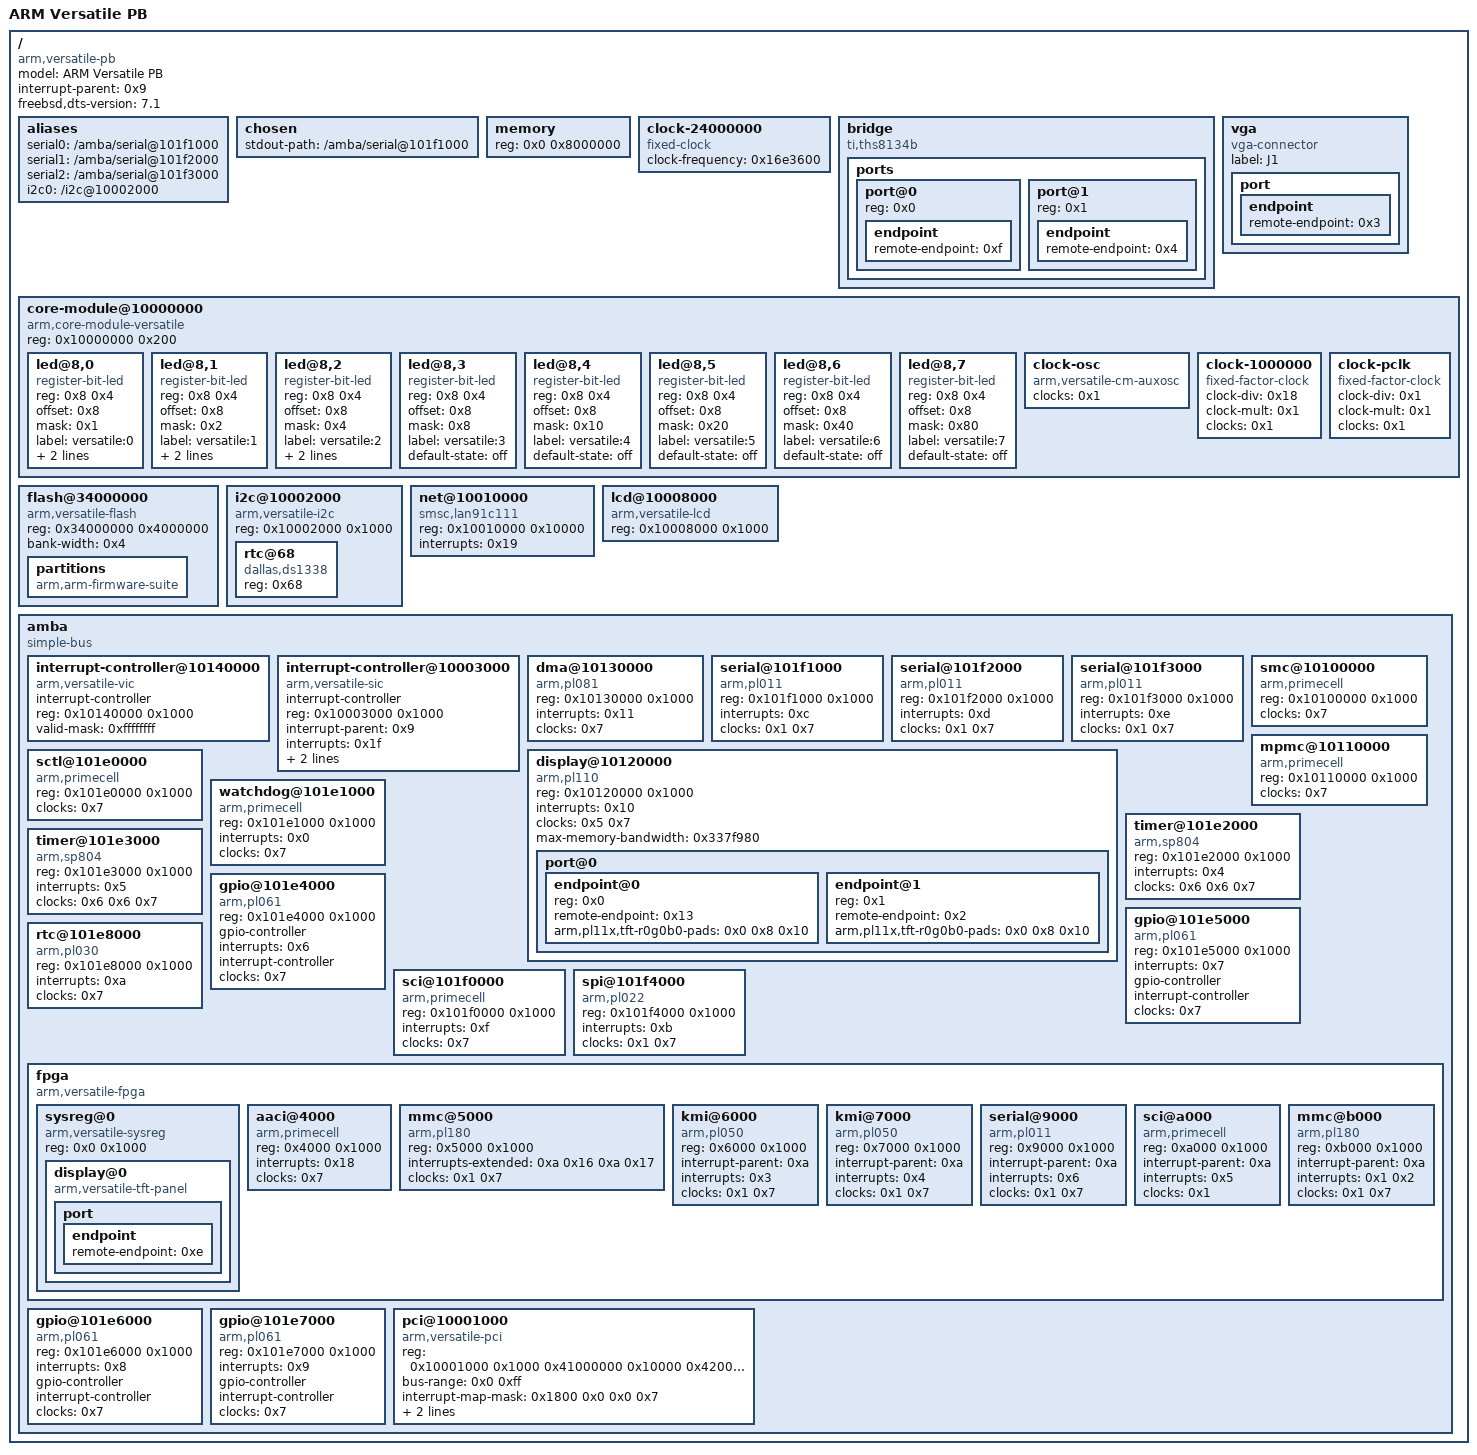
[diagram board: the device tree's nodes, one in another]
/dts-v1/;

/  {

	model = "ARM Versatile PB";
	compatible = "arm,versatile-pb";
	#address-cells = <0x1>;
	#size-cells = <0x1>;
	interrupt-parent = <0x9>;
	freebsd,dts-version = "7.1";
	aliases {

		serial0 = "/amba/serial@101f1000";
		serial1 = "/amba/serial@101f2000";
		serial2 = "/amba/serial@101f3000";
		i2c0 = "/i2c@10002000";
	};
	chosen {

		stdout-path = "/amba/serial@101f1000";
	};
	memory {

		device_type = "memory";
		reg = <0x0 0x8000000>;
	};
	clock-24000000 {

		#clock-cells = <0x0>;
		compatible = "fixed-clock";
		clock-frequency = <0x16e3600>;
		phandle = <0x1>;
	};
	bridge {

		compatible = "ti,ths8134b", "ti,ths8134";
		ports {

			#address-cells = <0x1>;
			#size-cells = <0x0>;
			port@0 {

				reg = <0x0>;
				endpoint {

					remote-endpoint = <0xf>;
					phandle = <0x2>;
				};
			};
			port@1 {

				reg = <0x1>;
				endpoint {

					remote-endpoint = <0x4>;
					phandle = <0x3>;
				};
			};
		};
	};
	vga {

		compatible = "vga-connector";
		label = "J1";
		port {

			endpoint {

				remote-endpoint = <0x3>;
				phandle = <0x4>;
			};
		};
	};
	core-module@10000000 {

		compatible = "arm,core-module-versatile", "syscon", "simple-mfd";
		reg = <0x10000000 0x200>;
		ranges = <0x0 0x10000000 0x200>;
		#address-cells = <0x1>;
		#size-cells = <0x1>;
		led@8,0 {

			compatible = "register-bit-led";
			reg = <0x8 0x4>;
			offset = <0x8>;
			mask = <0x1>;
			label = "versatile:0";
			linux,default-trigger = "heartbeat";
			default-state = "on";
		};
		led@8,1 {

			compatible = "register-bit-led";
			reg = <0x8 0x4>;
			offset = <0x8>;
			mask = <0x2>;
			label = "versatile:1";
			linux,default-trigger = "mmc0";
			default-state = "off";
		};
		led@8,2 {

			compatible = "register-bit-led";
			reg = <0x8 0x4>;
			offset = <0x8>;
			mask = <0x4>;
			label = "versatile:2";
			linux,default-trigger = "cpu0";
			default-state = "off";
		};
		led@8,3 {

			compatible = "register-bit-led";
			reg = <0x8 0x4>;
			offset = <0x8>;
			mask = <0x8>;
			label = "versatile:3";
			default-state = "off";
		};
		led@8,4 {

			compatible = "register-bit-led";
			reg = <0x8 0x4>;
			offset = <0x8>;
			mask = <0x10>;
			label = "versatile:4";
			default-state = "off";
		};
		led@8,5 {

			compatible = "register-bit-led";
			reg = <0x8 0x4>;
			offset = <0x8>;
			mask = <0x20>;
			label = "versatile:5";
			default-state = "off";
		};
		led@8,6 {

			compatible = "register-bit-led";
			reg = <0x8 0x4>;
			offset = <0x8>;
			mask = <0x40>;
			label = "versatile:6";
			default-state = "off";
		};
		led@8,7 {

			compatible = "register-bit-led";
			reg = <0x8 0x4>;
			offset = <0x8>;
			mask = <0x80>;
			label = "versatile:7";
			default-state = "off";
		};
		clock-osc {

			#clock-cells = <0x0>;
			compatible = "arm,versatile-cm-auxosc";
			clocks = <0x1>;
			phandle = <0x5>;
		};
		clock-1000000 {

			#clock-cells = <0x0>;
			compatible = "fixed-factor-clock";
			clock-div = <0x18>;
			clock-mult = <0x1>;
			clocks = <0x1>;
			phandle = <0x6>;
		};
		clock-pclk {

			#clock-cells = <0x0>;
			compatible = "fixed-factor-clock";
			clock-div = <0x1>;
			clock-mult = <0x1>;
			clocks = <0x1>;
			phandle = <0x7>;
		};
	};
	flash@34000000 {

		compatible = "arm,versatile-flash", "cfi-flash";
		reg = <0x34000000 0x4000000>;
		bank-width = <0x4>;
		partitions {

			compatible = "arm,arm-firmware-suite";
		};
	};
	i2c@10002000 {

		#address-cells = <0x1>;
		#size-cells = <0x0>;
		compatible = "arm,versatile-i2c";
		reg = <0x10002000 0x1000>;
		phandle = <0x8>;
		rtc@68 {

			compatible = "dallas,ds1338";
			reg = <0x68>;
		};
	};
	net@10010000 {

		compatible = "smsc,lan91c111";
		reg = <0x10010000 0x10000>;
		interrupts = <0x19>;
	};
	lcd@10008000 {

		compatible = "arm,versatile-lcd";
		reg = <0x10008000 0x1000>;
	};
	amba {

		compatible = "simple-bus";
		#address-cells = <0x1>;
		#size-cells = <0x1>;
		ranges;
		interrupt-controller@10140000 {

			compatible = "arm,versatile-vic";
			interrupt-controller;
			#interrupt-cells = <0x1>;
			reg = <0x10140000 0x1000>;
			valid-mask = <0xffffffff>;
			phandle = <0x9>;
		};
		interrupt-controller@10003000 {

			compatible = "arm,versatile-sic";
			interrupt-controller;
			#interrupt-cells = <0x1>;
			reg = <0x10003000 0x1000>;
			interrupt-parent = <0x9>;
			interrupts = <0x1f>;
			clear-mask = <0xffffffff>;
			valid-mask = <0x7fe003ff>;
			phandle = <0xa>;
		};
		dma@10130000 {

			compatible = "arm,pl081", "arm,primecell";
			reg = <0x10130000 0x1000>;
			interrupts = <0x11>;
			clocks = <0x7>;
			clock-names = "apb_pclk";
		};
		serial@101f1000 {

			compatible = "arm,pl011", "arm,primecell";
			reg = <0x101f1000 0x1000>;
			interrupts = <0xc>;
			clocks = <0x1 0x7>;
			clock-names = "uartclk", "apb_pclk";
			phandle = <0xb>;
		};
		serial@101f2000 {

			compatible = "arm,pl011", "arm,primecell";
			reg = <0x101f2000 0x1000>;
			interrupts = <0xd>;
			clocks = <0x1 0x7>;
			clock-names = "uartclk", "apb_pclk";
			phandle = <0xc>;
		};
		serial@101f3000 {

			compatible = "arm,pl011", "arm,primecell";
			reg = <0x101f3000 0x1000>;
			interrupts = <0xe>;
			clocks = <0x1 0x7>;
			clock-names = "uartclk", "apb_pclk";
			phandle = <0xd>;
		};
		smc@10100000 {

			compatible = "arm,primecell";
			reg = <0x10100000 0x1000>;
			clocks = <0x7>;
			clock-names = "apb_pclk";
		};
		mpmc@10110000 {

			compatible = "arm,primecell";
			reg = <0x10110000 0x1000>;
			clocks = <0x7>;
			clock-names = "apb_pclk";
		};
		display@10120000 {

			compatible = "arm,pl110", "arm,primecell";
			reg = <0x10120000 0x1000>;
			interrupts = <0x10>;
			clocks = <0x5 0x7>;
			clock-names = "clcdclk", "apb_pclk";
			max-memory-bandwidth = <0x337f980>;
			port@0 {

				#address-cells = <0x1>;
				#size-cells = <0x0>;
				endpoint@0 {

					reg = <0x0>;
					remote-endpoint = <0x13>;
					arm,pl11x,tft-r0g0b0-pads = <0x0 0x8 0x10>;
					phandle = <0xe>;
				};
				endpoint@1 {

					reg = <0x1>;
					remote-endpoint = <0x2>;
					arm,pl11x,tft-r0g0b0-pads = <0x0 0x8 0x10>;
					phandle = <0xf>;
				};
			};
		};
		sctl@101e0000 {

			compatible = "arm,primecell";
			reg = <0x101e0000 0x1000>;
			clocks = <0x7>;
			clock-names = "apb_pclk";
		};
		watchdog@101e1000 {

			compatible = "arm,primecell";
			reg = <0x101e1000 0x1000>;
			interrupts = <0x0>;
			clocks = <0x7>;
			clock-names = "apb_pclk";
		};
		timer@101e2000 {

			compatible = "arm,sp804", "arm,primecell";
			reg = <0x101e2000 0x1000>;
			interrupts = <0x4>;
			clocks = <0x6 0x6 0x7>;
			clock-names = "timer0", "timer1", "apb_pclk";
		};
		timer@101e3000 {

			compatible = "arm,sp804", "arm,primecell";
			reg = <0x101e3000 0x1000>;
			interrupts = <0x5>;
			clocks = <0x6 0x6 0x7>;
			clock-names = "timer0", "timer1", "apb_pclk";
		};
		gpio@101e4000 {

			compatible = "arm,pl061", "arm,primecell";
			reg = <0x101e4000 0x1000>;
			gpio-controller;
			interrupts = <0x6>;
			#gpio-cells = <0x2>;
			interrupt-controller;
			#interrupt-cells = <0x2>;
			clocks = <0x7>;
			clock-names = "apb_pclk";
			phandle = <0x10>;
		};
		gpio@101e5000 {

			compatible = "arm,pl061", "arm,primecell";
			reg = <0x101e5000 0x1000>;
			interrupts = <0x7>;
			gpio-controller;
			#gpio-cells = <0x2>;
			interrupt-controller;
			#interrupt-cells = <0x2>;
			clocks = <0x7>;
			clock-names = "apb_pclk";
			phandle = <0x11>;
		};
		rtc@101e8000 {

			compatible = "arm,pl030", "arm,primecell";
			reg = <0x101e8000 0x1000>;
			interrupts = <0xa>;
			clocks = <0x7>;
			clock-names = "apb_pclk";
		};
		sci@101f0000 {

			compatible = "arm,primecell";
			reg = <0x101f0000 0x1000>;
			interrupts = <0xf>;
			clocks = <0x7>;
			clock-names = "apb_pclk";
		};
		spi@101f4000 {

			compatible = "arm,pl022", "arm,primecell";
			reg = <0x101f4000 0x1000>;
			interrupts = <0xb>;
			clocks = <0x1 0x7>;
			clock-names = "sspclk", "apb_pclk";
		};
		fpga {

			compatible = "arm,versatile-fpga", "simple-bus";
			#address-cells = <0x1>;
			#size-cells = <0x1>;
			ranges = <0x0 0x10000000 0x10000>;
			sysreg@0 {

				compatible = "arm,versatile-sysreg", "syscon", "simple-mfd";
				reg = <0x0 0x1000>;
				display@0 {

					compatible = "arm,versatile-tft-panel";
					phandle = <0x12>;
					port {

						endpoint {

							remote-endpoint = <0xe>;
							phandle = <0x13>;
						};
					};
				};
			};
			aaci@4000 {

				compatible = "arm,primecell";
				reg = <0x4000 0x1000>;
				interrupts = <0x18>;
				clocks = <0x7>;
				clock-names = "apb_pclk";
			};
			mmc@5000 {

				compatible = "arm,pl180", "arm,primecell";
				reg = <0x5000 0x1000>;
				interrupts-extended = <0xa 0x16 0xa 0x17>;
				clocks = <0x1 0x7>;
				clock-names = "mclk", "apb_pclk";
			};
			kmi@6000 {

				compatible = "arm,pl050", "arm,primecell";
				reg = <0x6000 0x1000>;
				interrupt-parent = <0xa>;
				interrupts = <0x3>;
				clocks = <0x1 0x7>;
				clock-names = "KMIREFCLK", "apb_pclk";
			};
			kmi@7000 {

				compatible = "arm,pl050", "arm,primecell";
				reg = <0x7000 0x1000>;
				interrupt-parent = <0xa>;
				interrupts = <0x4>;
				clocks = <0x1 0x7>;
				clock-names = "KMIREFCLK", "apb_pclk";
			};
			serial@9000 {

				compatible = "arm,pl011", "arm,primecell";
				reg = <0x9000 0x1000>;
				interrupt-parent = <0xa>;
				interrupts = <0x6>;
				clocks = <0x1 0x7>;
				clock-names = "uartclk", "apb_pclk";
			};
			sci@a000 {

				compatible = "arm,primecell";
				reg = <0xa000 0x1000>;
				interrupt-parent = <0xa>;
				interrupts = <0x5>;
				clocks = <0x1>;
				clock-names = "apb_pclk";
			};
			mmc@b000 {

				compatible = "arm,pl180", "arm,primecell";
				reg = <0xb000 0x1000>;
				interrupt-parent = <0xa>;
				interrupts = <0x1 0x2>;
				clocks = <0x1 0x7>;
				clock-names = "mclk", "apb_pclk";
			};
		};
		gpio@101e6000 {

			compatible = "arm,pl061", "arm,primecell";
			reg = <0x101e6000 0x1000>;
			interrupts = <0x8>;
			gpio-controller;
			#gpio-cells = <0x2>;
			interrupt-controller;
			#interrupt-cells = <0x2>;
			clocks = <0x7>;
			clock-names = "apb_pclk";
			phandle = <0x14>;
		};
		gpio@101e7000 {

			compatible = "arm,pl061", "arm,primecell";
			reg = <0x101e7000 0x1000>;
			interrupts = <0x9>;
			gpio-controller;
			#gpio-cells = <0x2>;
			interrupt-controller;
			#interrupt-cells = <0x2>;
			clocks = <0x7>;
			clock-names = "apb_pclk";
			phandle = <0x15>;
		};
		pci@10001000 {

			compatible = "arm,versatile-pci";
			device_type = "pci";
			reg = <0x10001000 0x1000 0x41000000 0x10000 0x42000000 0x100000>;
			bus-range = <0x0 0xff>;
			#address-cells = <0x3>;
			#size-cells = <0x2>;
			#interrupt-cells = <0x1>;
			ranges = <0x1000000 0x0 0x0 0x43000000 0x0 0x10000 0x2000000 0x0 0x50000000 0x50000000 0x0 0x10000000 0x42000000 0x0 0x60000000 0x60000000 0x0 0x10000000>;
			interrupt-map-mask = <0x1800 0x0 0x0 0x7>;
			interrupt-map = <0x1800 0x0 0x0 0x1 0xa 0x1c 0x1800 0x0 0x0 0x2 0xa 0x1d 0x1800 0x0 0x0 0x3 0xa 0x1e 0x1800 0x0 0x0 0x4 0xa 0x1b 0x1000 0x0 0x0 0x1 0xa 0x1b 0x1000 0x0 0x0 0x2 0xa 0x1c 0x1000 0x0 0x0 0x3 0xa 0x1d 0x1000 0x0 0x0 0x4 0xa 0x1e 0x800 0x0 0x0 0x1 0xa 0x1e 0x800 0x0 0x0 0x2 0xa 0x1b 0x800 0x0 0x0 0x3 0xa 0x1c 0x800 0x0 0x0 0x4 0xa 0x1d 0x0 0x0 0x0 0x1 0xa 0x1d 0x0 0x0 0x0 0x2 0xa 0x1e 0x0 0x0 0x0 0x3 0xa 0x1b 0x0 0x0 0x0 0x4 0xa 0x1c>;
		};
	};
	__symbols__ {

		gpio3 = "/amba/gpio@101e7000";
		gpio2 = "/amba/gpio@101e6000";
		panel_in = "/amba/fpga/sysreg@0/display@0/port/endpoint";
		panel = "/amba/fpga/sysreg@0/display@0";
		gpio1 = "/amba/gpio@101e5000";
		gpio0 = "/amba/gpio@101e4000";
		clcd_pads_vga_dac = "/amba/display@10120000/port@0/endpoint@1";
		clcd_pads_panel = "/amba/display@10120000/port@0/endpoint@0";
		uart2 = "/amba/serial@101f3000";
		uart1 = "/amba/serial@101f2000";
		uart0 = "/amba/serial@101f1000";
		sic = "/amba/interrupt-controller@10003000";
		vic = "/amba/interrupt-controller@10140000";
		i2c0 = "/i2c@10002000";
		pclk = "/core-module@10000000/clock-pclk";
		timclk = "/core-module@10000000/clock-1000000";
		osc1 = "/core-module@10000000/clock-osc";
		vga_con_in = "/vga/port/endpoint";
		vga_bridge_out = "/bridge/ports/port@1/endpoint";
		vga_bridge_in = "/bridge/ports/port@0/endpoint";
		xtal24mhz = "/clock-24000000";
	};
};
